VERSION ""

NS_ :

BS_:
BU_: Calib Configuration PedalMapping AnalogNode
BO_ 2147483680 Calib: 8 Calib
   SG_ SensorSelect : 0|1@0+ (1,0) [0|11] "" Vector__XXX
   SG_ CalibSelect : 1|1@0- (1,0) [0|1] "" Vector__XXX

BO_ 2147483671 ChangePedalProfile: 8 PedalMapping
   SG_ ProfileType M : 0|1@1+ (1,0) [0|1] "" Vector__XXX
   SG_ ProfileSlotCustom m1 : 1|1@1+ (1,0) [0|9] "" Vector__XXX
   SG_ ProfileSlotPreset m0 : 1|1@1+ (1,0) [0|2] "" Vector__XXX

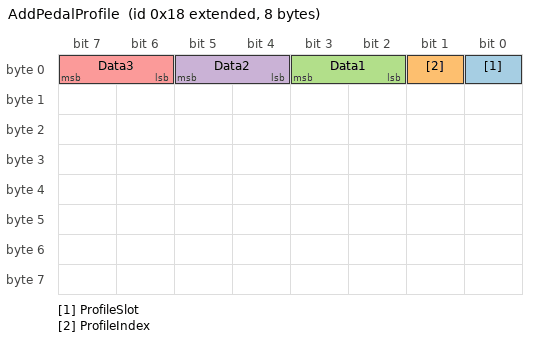
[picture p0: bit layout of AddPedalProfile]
BO_ 2147483672 AddPedalProfile: 8 PedalMapping
   SG_ ProfileSlot : 0|1@1+ (1,0) [0|20] "" Vector__XXX
   SG_ ProfileIndex : 1|1@1+ (1,0) [0|8] "" Vector__XXX
   SG_ Data1 : 2|2@1- (1,0) [-32768|32767] "" Vector__XXX
   SG_ Data2 : 4|2@1- (1,0) [-32768|32767] "" AnalogNode
   SG_ Data3 : 6|2@1- (1,0) [-32768|32767] "" AnalogNode

BO_ 2147483673 SaveToFlash: 0 PedalMapping

BO_ 2147483664 ChangeConfig: 1 Configuration
   SG_ Config : 0|1@1+ (1,0) [1|4] "" Vector__XXX

CM_ BO_ 2147483680 "Starts calibration";
CM_ SG_ 2147483680 CalibSelect "High_or_low_calibration_value";
CM_ SG_ 2147483671 ProfileType "Mux_switch_for_preset_or_custom_profiles.";
CM_ SG_ 2147483671 ProfileSlotCustom "Pick_between_10_custom_profile_slots.";
CM_ SG_ 2147483671 ProfileSlotPreset "Pick_between_2_preset_profiles.";
CM_ SG_ 2147483672 ProfileSlot "Profile_picker";
CM_ SG_ 2147483672 ProfileIndex "Index_in_the_21_element_array_to_send_the_3_elements_to.";
BA_DEF_ BO_ "GenMsgBackgroundColor" STRING ;
BA_DEF_ BO_ "GenMsgForegroundColor" STRING ;
BA_DEF_ BO_ "filterlabeling" INT 0 0;
BA_DEF_ BO_ "filterlabeling" INT 0 0;
BA_DEF_ BO_ "filterlabeling" INT 0 0;
BA_DEF_ BO_ "filterlabeling" INT 0 0;
BA_DEF_ BO_ "filterlabeling" INT 0 0;
BA_DEF_ BO_ "filterlabeling" INT 0 0;
BA_DEF_ BO_ "filterlabeling" INT 0 0;
BA_DEF_DEF_ "GenMsgBackgroundColor" "#ffffff";
BA_DEF_DEF_ "GenMsgForegroundColor" "#000000";
BA_DEF_DEF_ "filterlabeling" 1;
BA_DEF_DEF_ "filterlabeling" 1;
VAL_ 2147483680 SensorSelect 0 "No Description";
VAL_ 2147483680 CalibSelect 0 "Low" 1 "High" 1 "Default_invalid_value";
VAL_ 2147483671 ProfileType 0 "Preset_profiles" 1 "Custom_profiles";
VAL_ 2147483671 ProfileSlotPreset 0 "Linear_profile" 1 "Parabolic_profile";
